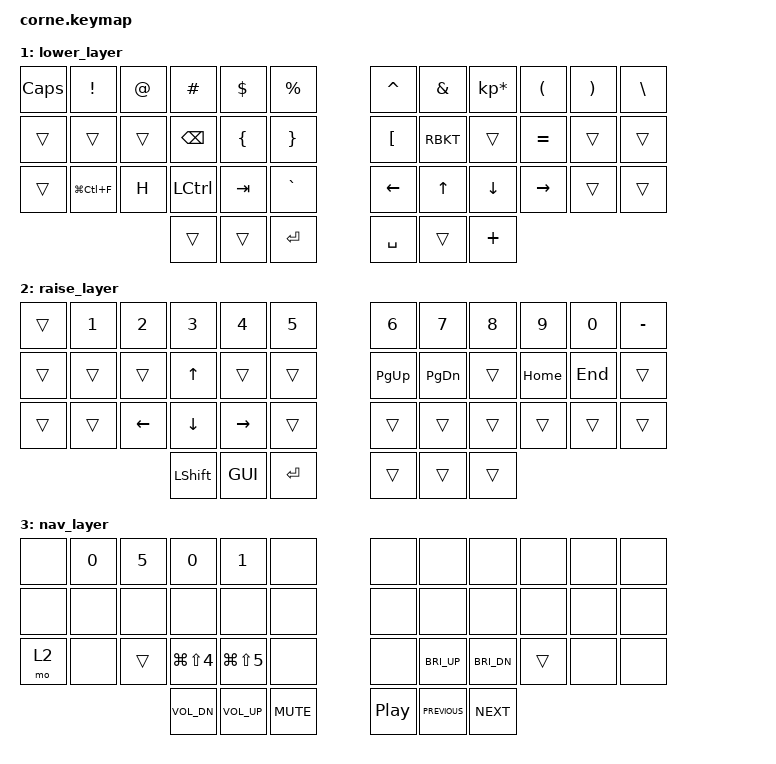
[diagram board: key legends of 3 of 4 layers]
/*
 * Copyright (c) 2020 The ZMK Contributors
 *
 * SPDX-License-Identifier: MIT
 */

#include <behaviors.dtsi>
#include <dt-bindings/zmk/keys.h>
#include <dt-bindings/zmk/bt.h>
#define DEFAULT 0
#define LOEWR   1
#define RAISE   2
#define NAVI    3
/{
        

        keymap {
                compatible = "zmk,keymap";

                default_layer {
// -----------------------------------------------------------------------------------------
// |  TAB |  Q  |  W  |  E  |  R  |  T  |   |  Y  |  U   |  I  |  O  |  P  | BKSP |
// | CTRL |  A  |  S  |  D  |  F  |  G  |   |  H  |  J   |  K  |  L  |  ;  |  '   |
// | SHFT |  Z  |  X  |  C  |  V  |  B  |   |  N  |  M   |  ,  |  .  |  /  | ESC  |
//                    | GUI | LWR | SPC |   | ENT | RSE  | ALT |
                        bindings = <
   &kp ESC    &kp Q     &kp W        &kp E     &kp R     &kp T          &kp Y  &kp U  &kp I     &kp O     &kp P      &kp PIPE
   &kp LSHIFT &kp A     &kp S        &kp D     &kp F     &kp G          &kp H  &kp J  &kp K     &kp L     &kp SEMI   &mt RSHFT SQT
   &mo 1      &kp Z     &mo 3 X      &kp C     &kp V     &kp B          &kp N  &kp M  &kp COMMA &mo 3 DOT &kp FSLH   &mo 1
                        &kp LALT &kp LGUI &kp SPACE                     &kp RET &mo 2 BSPC &kp MINUS
                        >;
                };
                lower_layer {
// -----------------------------------------------------------------------------------------
// |  TAB |  1  |  2  |  3  |  4  |  5  |   |  6  |  7  |  8  |  9  |  0  | BKSP |
// | BTCLR| BT1 | BT2 | BT3 | BT4 | BT5 |   | LFT | DWN |  UP | RGT |     |      |
// | SHFT |     |     |     |     |     |   |     |     |     |     |     |      |
//                    | GUI |     | SPC |   | ENT |     | ALT |
                        bindings = <
   &kp CAPS  &kp EXCL         &kp AT    &kp HASH   &kp DLLR  &kp PRCNT        &kp CARET  &kp AMPS  &kp KP_MULTIPLY  &kp LPAR    &kp RPAR &kp BSLH
   &trans    &trans           &trans    &kp BSPC   &kp LBRC  &kp RBRC         &kp LBKT   &RBKT     &trans           &kp EQUAL   &trans   &trans
   &trans    &kp LG(LC(F))    &kp H     &kp LCTRL  &kp TAB   &kp GRAVE        &kp LEFT   &kp UP    &kp DOWN         &kp RIGHT   &trans   &trans
                        &trans     &trans       &kp RET                 &kp SPACE  &trans    &kp PLUS
                        >;
                };

                raise_layer {
// -----------------------------------------------------------------------------------------
// |  TAB |  !  |  @  |  #  |  $  |  %  |   |  ^  |  &  |  *  |  (  |  )  | BKSP |
// | CTRL |     |     |     |     |     |   |  -  |  =  |  [  |  ]  |  \  |  `   |
// | SHFT |     |     |     |     |     |   |  _  |  +  |  {  |  }  | "|" |  ~   |
//                    | GUI |     | SPC |   | ENT |     | ALT |
                        bindings = <
   &trans   &kp N1  &kp N2    &kp N3    &kp N4    &kp N5                &kp N6       &kp N7     &kp N8  &kp N9    &kp N0   &kp MINUS
   &trans   &trans  &trans    &kp UP    &trans    &trans                &kp PG_UP    &kp PG_DN  &trans  &kp HOME  &kp END  &trans
   &trans   &trans  &kp LEFT  &kp DOWN  &kp RIGHT &trans                &trans       &trans     &trans  &trans    &trans   &trans
                    	      &kp LSHFT &kp GUI   &kp RET               &trans       &trans     &trans
                        >;
                };

		nav_layer {
			bindings = <
				&none   &kp N0   &kp N5   &kp N0           &kp N1       &none         &none &none         &none        &none  &none &none
				&none   &none    &none    &none            &none        &none         &none &none        &none        &none  &none &none
				&mo 2   &none    &trans   &kp LG(LS(N4))   &kp LG(LS(N5))  &none         &none &kp C_BRI_UP  &kp C_BRI_DN &trans  &none &none
				                          &kp C_VOL_DN    &kp C_VOL_UP  &kp C_MUTE    &kp C_PLAY_PAUSE &kp C_PREVIOUS  &kp C_NEXT
				
			>;
		};
        };
};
